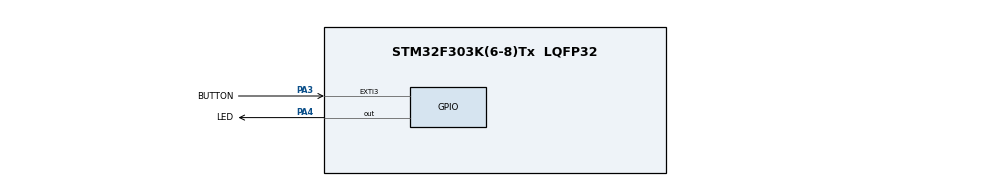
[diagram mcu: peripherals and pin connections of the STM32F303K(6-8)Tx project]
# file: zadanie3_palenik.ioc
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Mcu.Family=STM32F3
Mcu.Name=STM32F303K(6-8)Tx
Mcu.Package=LQFP32
NVIC.EXTI3_IRQn=true\:0\:0\:false\:false\:true\:true\:true\:true
NVIC.PriorityGroup=NVIC_PRIORITYGROUP_4
PA3.GPIO_Label=BUTTON
PA3.GPIO_ModeDefaultEXTI=GPIO_MODE_IT_FALLING
PA3.GPIO_PuPd=GPIO_PULLUP
PA3.Signal=GPXTI3
PA4.GPIO_Label=LED
PA4.Signal=GPIO_Output
ProjectManager.HeapSize=0x200
ProjectManager.StackSize=0x400
ProjectManager.TargetToolchain=STM32CubeIDE
RCC.AHBFreq_Value=8000000
RCC.APB1Freq_Value=8000000
RCC.APB2Freq_Value=8000000
RCC.CortexFreq_Value=8000000
RCC.HSE_VALUE=8000000
RCC.HSI_VALUE=8000000
RCC.SYSCLKFreq_VALUE=8000000
board=custom

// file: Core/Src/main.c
/* USER CODE BEGIN Header */
/**
  ******************************************************************************
  * @file           : main.c
  * @brief          : Main program body
  ******************************************************************************
  * @attention
  *
  * Copyright (c) 2023 STMicroelectronics.
  * All rights reserved.
  *
  * This software is licensed under terms that can be found in the LICENSE file
  * in the root directory of this software component.
  * If no LICENSE file comes with this software, it is provided AS-IS.
  *
  ******************************************************************************
  */
/* USER CODE END Header */
#include "main.h"
#include "gpio.h"

void SystemClock_Config(void);

EDGE_TYPE edge = NONE;
uint8_t count = 0;
uint8_t previous_state = 1;
uint8_t toggle_led = 0;

int main(void)
{

  /* MCU Configuration--------------------------------------------------------*/

  /* Reset of all peripherals, Initializes the Flash interface and the Systick. */
  LL_APB2_GRP1_EnableClock(LL_APB2_GRP1_PERIPH_SYSCFG);
  LL_APB1_GRP1_EnableClock(LL_APB1_GRP1_PERIPH_PWR);

  /* System interrupt init*/
  NVIC_SetPriorityGrouping(NVIC_PRIORITYGROUP_4);

  /* SysTick_IRQn interrupt configuration */
  NVIC_SetPriority(SysTick_IRQn, NVIC_EncodePriority(NVIC_GetPriorityGrouping(),15, 0));

  /* Configure the system clock */
  SystemClock_Config();

  /* Initialize all configured peripherals */
  MX_GPIO_Init();

  /* Infinite loop */
  while (1)
  {

	  if(toggle_led){
		  if(!(LED_GPIO_Port->ODR & (1 << LED_PIN_POS))){
			  LED_GPIO_Port->BSRR |= (1 << LED_PIN_POS);
			  toggle_led = 0;
		  }
		  else{
			  LED_GPIO_Port->BRR |= (1 << LED_PIN_POS);
			  toggle_led = 0;
		  }
	  }

  }
}

/**
  * @brief This function handles EXTI line 3 interrupt.
  */
void EXTI3_IRQHandler(void)
{
  /* USER CODE BEGIN EXTI3_IRQn 0 */
	if(!toggle_led){
		edge = edgeDetect(SAMPLE_COUNT);
		if(edge == FALL){
			toggle_led = 1;
		}
		LL_mDelay(10);
	}

  /* USER CODE END EXTI3_IRQn 0 */

	if (LL_EXTI_IsActiveFlag_0_31(LL_EXTI_LINE_3) != RESET)
	{
		LL_EXTI_ClearFlag_0_31(LL_EXTI_LINE_3);
	}
}

void SystemClock_Config(void)
{
  LL_FLASH_SetLatency(LL_FLASH_LATENCY_0);
  while(LL_FLASH_GetLatency()!= LL_FLASH_LATENCY_0)
  {
  }
  LL_RCC_HSI_Enable();

   /* Wait till HSI is ready */
  while(LL_RCC_HSI_IsReady() != 1)
  {

  }
  LL_RCC_HSI_SetCalibTrimming(16);
  LL_RCC_SetAHBPrescaler(LL_RCC_SYSCLK_DIV_1);
  LL_RCC_SetAPB1Prescaler(LL_RCC_APB1_DIV_1);
  LL_RCC_SetAPB2Prescaler(LL_RCC_APB2_DIV_1);
  LL_RCC_SetSysClkSource(LL_RCC_SYS_CLKSOURCE_HSI);

   /* Wait till System clock is ready */
  while(LL_RCC_GetSysClkSource() != LL_RCC_SYS_CLKSOURCE_STATUS_HSI)
  {

  }
  LL_Init1msTick(8000000);
  LL_SetSystemCoreClock(8000000);
}

/* USER CODE BEGIN 4 */
EDGE_TYPE edgeDetect(uint8_t samples)
{
	while(count < samples){

		uint8_t pin_state = BUTTON_GET_STATE;

		if(pin_state && !previous_state){
			previous_state = 1;
			count = 0;
		}
		else if(!pin_state && count < samples){
			previous_state = 0;
			count++;
			if(count == samples){
				count = 0;
				return FALL;
			}
		}
		LL_mDelay(10);
	}
	return NONE;
}
/* USER CODE END 4 */

void Error_Handler(void)
{
  __disable_irq();
  while (1)
  {
  }
}
